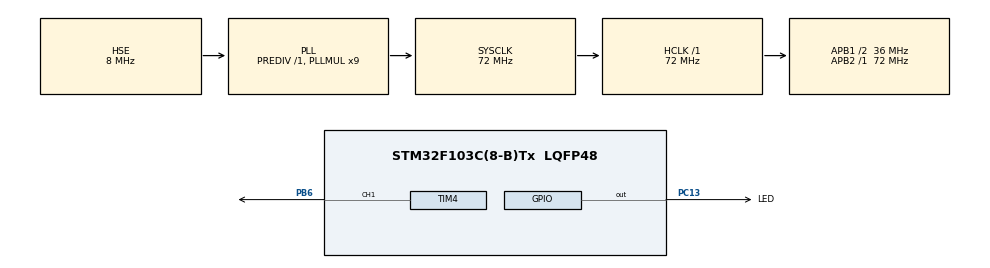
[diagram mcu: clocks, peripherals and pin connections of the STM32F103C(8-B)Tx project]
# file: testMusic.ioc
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Mcu.Family=STM32F1
Mcu.Name=STM32F103C(8-B)Tx
Mcu.Package=LQFP48
NVIC.PriorityGroup=NVIC_PRIORITYGROUP_4
PA13.Mode=Serial_Wire
PA13.Signal=SYS_JTMS-SWDIO
PA14.Mode=Serial_Wire
PA14.Signal=SYS_JTCK-SWCLK
PB6.Signal=S_TIM4_CH1
PC13-TAMPER-RTC.GPIO_Label=LED
PC13-TAMPER-RTC.Signal=GPIO_Output
PD0-OSC_IN.Mode=HSE-External-Oscillator
PD0-OSC_IN.Signal=RCC_OSC_IN
PD1-OSC_OUT.Mode=HSE-External-Oscillator
PD1-OSC_OUT.Signal=RCC_OSC_OUT
ProjectManager.HeapSize=0x200
ProjectManager.StackSize=0x400
ProjectManager.TargetToolchain=STM32CubeIDE
RCC.AHBFreq_Value=72000000
RCC.APB1CLKDivider=RCC_HCLK_DIV2
RCC.APB1Freq_Value=36000000
RCC.APB1TimFreq_Value=72000000
RCC.APB2Freq_Value=72000000
RCC.APB2TimFreq_Value=72000000
RCC.HCLKFreq_Value=72000000
RCC.PLLMUL=RCC_PLL_MUL9
RCC.PLLSourceVirtual=RCC_PLLSOURCE_HSE
RCC.SYSCLKFreq_VALUE=72000000
RCC.SYSCLKSource=RCC_SYSCLKSOURCE_PLLCLK
RCC.USBFreq_Value=72000000
SH.S_TIM4_CH1.0=TIM4_CH1,PWM Generation1 CH1
TIM4.AutoReloadPreload=TIM_AUTORELOAD_PRELOAD_ENABLE
TIM4.Channel-PWM\ Generation1\ CH1=TIM_CHANNEL_1
TIM4.OC1Preload_PWM=ENABLE
TIM4.OCPolarity_1=TIM_OCPOLARITY_LOW
TIM4.Period=1250-1
TIM4.Prescaler=7200-1
TIM4.Pulse-PWM\ Generation1\ CH1=625
board=custom

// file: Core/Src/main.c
/* USER CODE BEGIN Header */
/**
  ******************************************************************************
  * @file           : main.c
  * @brief          : Main program body
  ******************************************************************************
  * @attention
  *
  * <h2><center>&copy; Copyright (c) 2020 STMicroelectronics.
  * All rights reserved.</center></h2>
  *
  * This software component is licensed by ST under BSD 3-Clause license,
  * the "License"; You may not use this file except in compliance with the
  * License. You may obtain a copy of the License at:
  *                        opensource.org/licenses/BSD-3-Clause
  *
  ******************************************************************************
  */
/* USER CODE END Header */
#include "main.h"
#include "tim.h"
#include "gpio.h"

void SystemClock_Config(void);

/* USER CODE BEGIN 0 */
uint16_t tone[] ={250,262,294,330,350,393,441,495,525,589,661,700,786,882,990}; //音调
uint8_t music[]={5,5,6,5,8,7,5,5,6,5,9,8,5,5,12,10,8,7,6,11,
			11,10,8,9,8,5,5,8,5,5,12,10,8,7,6,11,11,10,8,9,8    //乐谱音调
};
uint8_t time[] = {1,2,2,2,2,4,1,2,2,2,2,4,1,2,2,2,1,4,
			 4,1,2,2,2,2,4,1,2,4,1,2,2,2,1,4, 4,1,2,2,2,2,4,4        //节拍时间
};

/* USER CODE END 0 */

int main(void)
{
  /* USER CODE BEGIN 1 */
	uint8_t mb = 0, tb = 0;
	uint16_t mv = 0;
	uint32_t arr = 0, pwm = 0;

  /* USER CODE END 1 */

  /* MCU Configuration--------------------------------------------------------*/

  /* Reset of all peripherals, Initializes the Flash interface and the Systick. */
  HAL_Init();

  /* Configure the system clock */
  SystemClock_Config();

  /* Initialize all configured peripherals */
  MX_GPIO_Init();
  MX_TIM4_Init();
  /* USER CODE BEGIN 2 */
  HAL_TIM_PWM_Start(&htim4, TIM_CHANNEL_1);
  /* USER CODE END 2 */

  /* Infinite loop */
  while (1)
  {

    /* USER CODE BEGIN 3 */
	  if((mb >= sizeof(music) / sizeof(music[0])) || (tb >= sizeof(time) / sizeof(time[0])))
	  {
		  mb = 0;
		  tb = 0;
	  } else {
		  mv = tone[music[mb]];
		  arr = 72000000 / (7200 * mv) - 1;
		  pwm = arr / 2;
		  TIM4->ARR = arr;
		  TIM4->CCR1 = pwm;
		  HAL_Delay(time[tb] * 200);
		  HAL_GPIO_TogglePin(LED_GPIO_Port, LED_Pin);
		  mb++;
		  tb++;
	  }
  }
  /* USER CODE END 3 */
}

void SystemClock_Config(void)
{
  RCC_OscInitTypeDef RCC_OscInitStruct = {0};
  RCC_ClkInitTypeDef RCC_ClkInitStruct = {0};

  /** Initializes the RCC Oscillators according to the specified parameters
  * in the RCC_OscInitTypeDef structure.
  */
  RCC_OscInitStruct.OscillatorType = RCC_OSCILLATORTYPE_HSE;
  RCC_OscInitStruct.HSEState = RCC_HSE_ON;
  RCC_OscInitStruct.HSEPredivValue = RCC_HSE_PREDIV_DIV1;
  RCC_OscInitStruct.HSIState = RCC_HSI_ON;
  RCC_OscInitStruct.PLL.PLLState = RCC_PLL_ON;
  RCC_OscInitStruct.PLL.PLLSource = RCC_PLLSOURCE_HSE;
  RCC_OscInitStruct.PLL.PLLMUL = RCC_PLL_MUL9;
  if (HAL_RCC_OscConfig(&RCC_OscInitStruct) != HAL_OK)
  {
    Error_Handler();
  }
  /** Initializes the CPU, AHB and APB buses clocks
  */
  RCC_ClkInitStruct.ClockType = RCC_CLOCKTYPE_HCLK|RCC_CLOCKTYPE_SYSCLK
                              |RCC_CLOCKTYPE_PCLK1|RCC_CLOCKTYPE_PCLK2;
  RCC_ClkInitStruct.SYSCLKSource = RCC_SYSCLKSOURCE_PLLCLK;
  RCC_ClkInitStruct.AHBCLKDivider = RCC_SYSCLK_DIV1;
  RCC_ClkInitStruct.APB1CLKDivider = RCC_HCLK_DIV2;
  RCC_ClkInitStruct.APB2CLKDivider = RCC_HCLK_DIV1;

  if (HAL_RCC_ClockConfig(&RCC_ClkInitStruct, FLASH_LATENCY_2) != HAL_OK)
  {
    Error_Handler();
  }
}

void Error_Handler(void)
{
}

/************************ (C) COPYRIGHT STMicroelectronics *****END OF FILE****/
